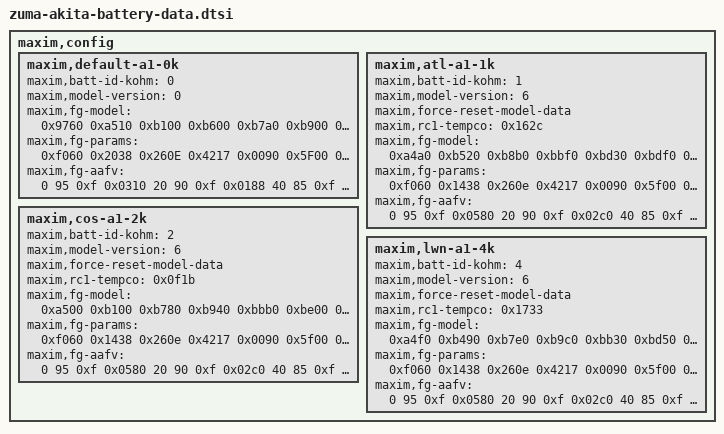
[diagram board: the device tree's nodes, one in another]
// SPDX-License-Identifier: GPL-2.0-only
/*
 * Battery device tree entries
 *
 * Copyright 2022 Google LLC
 *
 */

maxim,config {

	/* R4_p1_gen.ini, 2021-01-21, b/174787673, generic model */
	maxim,default-a1-0k {
		maxim,batt-id-kohm = <0>;
		maxim,model-version = <0>;
		maxim,fg-model = /bits/ 16 <
			0x9760 0xa510 0xb100 0xb600 0xb7a0 0xb900 0xba70 0xbc70
			0xbde0 0xbfc0 0xc250 0xc510 0xc990 0xcea0 0xd040 0xd750
			0x0060 0x0120 0x0200 0x0710 0x0e80 0x0df0 0x1430 0x1bd0
			0x1520 0x0d70 0x0950 0x08e0 0x0800 0x0780 0x06b0 0x01e0
			0x0100 0x0100 0x0100 0x0100 0x0100 0x0100 0x0100 0x0100
			0x0100 0x0100 0x0100 0x0100 0x0100 0x0100 0x0100 0x0100
		>;
		maxim,fg-params = /bits/ 16 <
			/* 0x0036 */	0xf060	/* IAvgEmpty */
			/* 0x002a */	0x2038	/* RelaxCFG */
			/* 0x0028 */	0x260E	/* LearnCFG */
			/* 0x001D */	0x4217	/* Config */
			/* 0x00BB */	0x0090	/* Config2 */
			/* 0x0013 */	0x5F00	/* FullSOCthr */
			/* 0x0035 */	0x0994	/* FullCAPRep */
			/* 0x0018 */	0x0994	/* DesignCap */
			/* 0x0046 */	0x0c80	/* dPacc */
			/* 0x0045 */	0x0099	/* dQacc */
			/* 0x0023 */	0x0994	/* FullCAPNom */
			/* 0x003A */	0xA561	/* V_empty */
			/* 0x0012 */	0x1100	/* QResidual00 */
			/* 0x0022 */	0x0800	/* QResidual10 */
			/* 0x0032 */	0x0301	/* QResidual20 */
			/* 0x0042 */	0x0302	/* QResidual30 */
			/* 0x0038 */	0x0700	/* RCOMP0 */
			/* 0x0039 */	0x223E	/* TempCo */
			/* 0x001E */	0x0310	/* ICHGTerm */
			/* 0x002C */	0xED51	/* TGain */
			/* 0x002D */	0x1EBA	/* TOff */
			/* 0x00B9 */	0x0014	/* Curve */
			/* 0x002B */	0x3870	/* MiscCFG */
			/* 0x0004 */	0x0000	/* AtRate */
			/* 0x0049 */	0x2241	/* convgcfg */
			/* 0x0029 */	0xc623	/* FilterCFG */
			/* 0x003c */	0x2D00	/* TaskPeriod */
		>;
		maxim,fg-aafv = /bits/ 32 <
			  0   95  0xf  0x0310
			 20   90  0xf  0x0188
			 40   85  0xf  0x0188
			 60   80  0xf  0x0188
			 80   75  0xf  0x0188
			130   63  0xf  0x0188
		>;
	};

	/* AK3_ATL(3420)_RC2_5mOhm_Rev5.txt b/322548406#comment1 */
	maxim,atl-a1-1k {
		maxim,batt-id-kohm = <1>;
		maxim,model-version = <6>;
		maxim,force-reset-model-data;
		maxim,rc1-tempco = /bits/ 16 <0x162c>;
		maxim,fg-model = /bits/ 16 <
			0xa4a0 0xb520 0xb8b0 0xbbf0 0xbd30 0xbdf0 0xbef0 0xc000
			0xc1c0 0xc420 0xc820 0xcbb0 0xcef0 0xd270 0xd5a0 0xdd30
			0x0090 0x0d30 0x0a00 0x0620 0x3c00 0x1c00 0x0960 0x0ce0
			0x0bf0 0x05f0 0x07d0 0x07f0 0x05d0 0x05b0 0x06f0 0x06f0
			0x0200 0x0200 0x0200 0x0200 0x0200 0x0200 0x0200 0x0200
			0x0200 0x0200 0x0200 0x0200 0x0200 0x0200 0x0200 0x0200
		>;
		maxim,fg-params = /bits/ 16 <
			/* 0x0036 */	0xf060	/* nIAvgEmpty -> IAvgEmpty */
			/* 0x002a */	0x1438	/* nRelaxCFG -> RelaxCFG */
			/* 0x0028 */	0x260e	/* nLearnCFG -> LearnCFG */
			/* 0x001D */	0x4217	/* Config: */
			/* 0x00BB */	0x0090	/* Config2: OCVQen|DSOCIi */
			/* 0x0013 */	0x5f00	/* nFullSOCThr -> FullSOCThr*/
			/* 0x0035 */	0x08C3	/* nFullCapRep */
			/* 0x0018 */	0x08C3	/* nDesignCap */
			/* 0x0046 */	0x3200	/* dPacc */
			/* 0x0045 */	0x0230	/* dQacc */
			/* 0x0023 */	0x08C3	/* nFullCapNom */
			/* 0x003A */	0xa561	/* V_empty */
			/* 0x0012 */	0x2080	/* nQRTable00 -> QResidual00 */
			/* 0x0022 */	0x0e80	/* nQRTable10 -> QResidual10 */
			/* 0x0032 */	0x0580	/* nQRTable20 -> QResidual20 */
			/* 0x0042 */	0x0400	/* nQRTable30 -> QResidual30 */
			/* 0x0038 */	0x09a0	/* nRcomp0 */
			/* 0x0039 */	0x1002	/* nTempco */
			/* 0x001E */	0x0580	/* ICHGTerm */
			/* 0x002C */	0xED51	/* *TGain */
			/* 0x002D */	0x1EBA	/* *TOFF */
			/* 0x00B9 */	0x0014	/* *TCurve */
			/* 0x002B */	0x6070	/* *nMiscCfg */
			/* 0x0004 */	0x1900	/* AtRate @ 0x04 */
			/* 0x0049 */	0x2241	/* convgcfg */
			/* 0x0029 */	0x0613	/* FilterCFG */
			/* 0x003c */	0x2D00	/* TaskPeriod */
			/* 0x002e */	0x0400	/* CGain */
		>;
		maxim,fg-aafv = /bits/ 32 <
			  0   95  0xf  0x0580
			 20   90  0xf  0x02c0
			 40   85  0xf  0x02c0
			 60   80  0xf  0x02c0
			 80   75  0xf  0x02c0
			130   63  0xf  0x02c0
		>;
	};

    /* AK3_COS(3418)_RC2_5mOhm_Rev5.txt b/322548406#comment2 */
	maxim,cos-a1-2k {
		maxim,batt-id-kohm = <2>;
		maxim,model-version = <6>;
		maxim,force-reset-model-data;
		maxim,rc1-tempco = /bits/ 16 <0x0f1b>;
		maxim,fg-model = /bits/ 16 <
			0xa500 0xb100 0xb780 0xb940 0xbbb0 0xbe00 0xc090 0xc370
			0xc730 0xca60 0xcc60 0xcec0 0xd460 0xd740 0xda90 0xdf60
			0x00d0 0x0350 0x0c30 0x0e00 0x1320 0x0f00 0x0da0 0x07e0
			0x05f0 0x08b0 0x0670 0x07a0 0x04b0 0x08e0 0x04f0 0x04f0
			0x0200 0x0200 0x0200 0x0200 0x0200 0x0200 0x0200 0x0200
			0x0200 0x0200 0x0200 0x0200 0x0200 0x0200 0x0200 0x0200
		>;
		maxim,fg-params = /bits/ 16 <
			/* 0x0036 */	0xf060	/* nIAvgEmpty -> IAvgEmpty */
			/* 0x002a */	0x1438	/* nRelaxCFG -> RelaxCFG */
			/* 0x0028 */	0x260e	/* nLearnCFG -> LearnCFG */
			/* 0x001D */	0x4217	/* Config: */
			/* 0x00BB */	0x0090	/* Config2: OCVQen|DSOCIi */
			/* 0x0013 */	0x5f00	/* nFullSOCThr -> FullSOCThr*/
			/* 0x0035 */	0x08b9	/* nFullCapRep */
			/* 0x0018 */	0x08b9	/* nDesignCap */
			/* 0x0046 */	0x3200	/* dPacc */
			/* 0x0045 */	0x022e	/* dQacc */
			/* 0x0023 */	0x08b9	/* nFullCapNom */
			/* 0x003A */	0xa561	/* V_empty */
			/* 0x0012 */	0x2000	/* nQRTable00 -> QResidual00 */
			/* 0x0022 */	0x0e80	/* nQRTable10 -> QResidual10 */
			/* 0x0032 */	0x0500	/* nQRTable20 -> QResidual20 */
			/* 0x0042 */	0x0480	/* nQRTable30 -> QResidual30 */
			/* 0x0038 */	0x0760	/* nRcomp0 */
			/* 0x0039 */	0x1202	/* nTempco */
			/* 0x001E */	0x0580	/* ICHGTerm */
			/* 0x002C */	0xED51	/* *TGain */
			/* 0x002D */	0x1EBA	/* *TOFF */
			/* 0x00B9 */	0x0014	/* *TCurve */
			/* 0x002B */	0x6070	/* *nMiscCfg */
			/* 0x0004 */	0x1900	/* AtRate @ 0x04 */
			/* 0x0049 */	0x2241	/* convgcfg */
			/* 0x0029 */	0x0613	/* FilterCFG */
			/* 0x003c */	0x2D00	/* TaskPeriod */
			/* 0x002e */	0x0400	/* CGain */
		>;
		maxim,fg-aafv = /bits/ 32 <
			  0   95  0xf  0x0580
			 20   90  0xf  0x02c0
			 40   85  0xf  0x02c0
			 60   80  0xf  0x02c0
			 80   75  0xf  0x02c0
			130   63  0xf  0x02c0
		>;
	};

	/* AK3_LWN(3419)_RC2_5mOhm_Rev5.txt b/322548406#comment1 */
	maxim,lwn-a1-4k {
		maxim,batt-id-kohm = <4>;
		maxim,model-version = <6>;
		maxim,force-reset-model-data;
		maxim,rc1-tempco = /bits/ 16 <0x1733>;
		maxim,fg-model = /bits/ 16 <
			0xa4f0 0xb490 0xb7e0 0xb9c0 0xbb30 0xbd50 0xc010 0xc050
			0xc2d0 0xc540 0xc920 0xcbd0 0xcf60 0xd2c0 0xd630 0xdc60
			0x0020 0x0a20 0x0d80 0x1010 0x1020 0x1140 0x2980 0x0b70
			0x08d0 0x05e0 0x09d0 0x05e0 0x05f0 0x06f0 0x06f0 0x06f0
			0x0200 0x0200 0x0200 0x0200 0x0200 0x0200 0x0200 0x0200
			0x0200 0x0200 0x0200 0x0200 0x0200 0x0200 0x0200 0x0200
		>;
		maxim,fg-params = /bits/ 16 <
			/* 0x0036 */	0xf060	/* nIAvgEmpty -> IAvgEmpty */
			/* 0x002a */	0x1438	/* nRelaxCFG -> RelaxCFG */
			/* 0x0028 */	0x260e	/* nLearnCFG -> LearnCFG */
			/* 0x001D */	0x4217	/* Config: */
			/* 0x00BB */	0x0090	/* Config2: OCVQen|DSOCIi */
			/* 0x0013 */	0x5f00	/* nFullSOCThr -> FullSOCThr*/
			/* 0x0035 */	0x08ad	/* nFullCapRep */
			/* 0x0018 */	0x08ad	/* nDesignCap */
			/* 0x0046 */	0x3200	/* dPacc */
			/* 0x0045 */	0x022b	/* dQacc */
			/* 0x0023 */	0x08ad	/* nFullCapNom */
			/* 0x003A */	0xa561	/* V_empty */
			/* 0x0012 */	0x2100	/* nQRTable00 -> QResidual00 */
			/* 0x0022 */	0x0d80	/* nQRTable10 -> QResidual10 */
			/* 0x0032 */	0x0580	/* nQRTable20 -> QResidual20 */
			/* 0x0042 */	0x0480	/* nQRTable30 -> QResidual30 */
			/* 0x0038 */	0x07d0	/* nRcomp0 */
			/* 0x0039 */	0x0c02	/* nTempco */
			/* 0x001E */	0x0580	/* ICHGTerm */
			/* 0x002C */	0xED51	/* *TGain */
			/* 0x002D */	0x1EBA	/* *TOFF */
			/* 0x00B9 */	0x0014	/* *TCurve */
			/* 0x002B */	0x6070	/* *nMiscCfg */
			/* 0x0004 */	0x1900	/* AtRate @ 0x04 */
			/* 0x0049 */	0x2241	/* convgcfg */
			/* 0x0029 */	0x0613	/* FilterCFG */
			/* 0x003c */	0x2D00	/* TaskPeriod */
			/* 0x002e */	0x0400	/* CGain */
		>;
		maxim,fg-aafv = /bits/ 32 <
			  0   95  0xf  0x0580
			 20   90  0xf  0x02c0
			 40   85  0xf  0x02c0
			 60   80  0xf  0x02c0
			 80   75  0xf  0x02c0
			130   63  0xf  0x02c0
		>;
	};
};
